# nrf9230_enga_cellrf register map
Vendor: Nordic Semiconductor; Series: nRF92; File version: 1
CPU: CM0 r0p0, little endian, no MPU, no FPU, 2 interrupt priority bits, 33 interrupts
Registers are 32-bit, read-write, reset 0x0 unless marked. A register's access mark holds for its fields unless they carry their own. Offsets are from the block's base; [hi:lo] are bit positions; 'fields as' and 'values as' point back to an identical list.

## RFPLL — RFPLL register map
Base 0x46047000
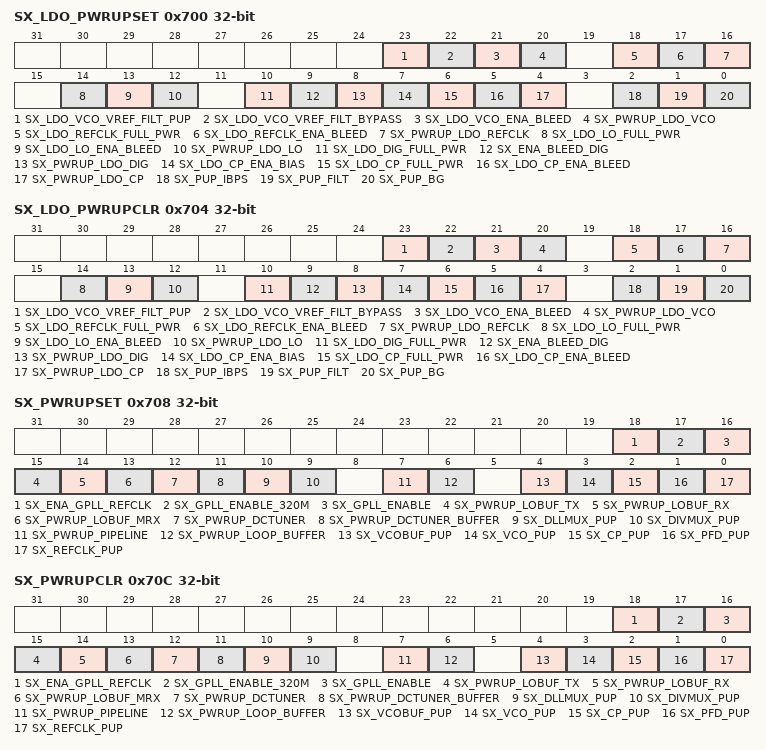
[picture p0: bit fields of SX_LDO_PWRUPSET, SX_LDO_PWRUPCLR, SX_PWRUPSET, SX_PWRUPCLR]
0x700 SX_LDO_PWRUPSET write-1-sets — SX LDO power power up register
  [all] fields
    1=SET (Unspecified); 0=NoEffect (Unspecified)
  [23] SX_LDO_VCO_VREF_FILT_PUP — Enable VREF voltage and its selection logic
  [22] SX_LDO_VCO_VREF_FILT_BYPASS — Bypass large R in VREF RC filter
  [21] SX_LDO_VCO_ENA_BLEED — LDO bleed
  [20] SX_PWRUP_LDO_VCO — LDO power up
  [18] SX_LDO_REFCLK_FULL_PWR — LDO full power
  [17] SX_LDO_REFCLK_ENA_BLEED — LDO bleed
  [16] SX_PWRUP_LDO_REFCLK — LDO power up
  [14] SX_LDO_LO_FULL_PWR — LDO full power
  [13] SX_LDO_LO_ENA_BLEED — LDO bleed
  [12] SX_PWRUP_LDO_LO — LDO power up
  [10] SX_LDO_DIG_FULL_PWR — LDO full power
  [9] SX_ENA_BLEED_DIG — LDO bleed
  [8] SX_PWRUP_LDO_DIG — LDO power up
  [7] SX_LDO_CP_ENA_BIAS — LDO bias power up
  [6] SX_LDO_CP_FULL_PWR — LDO full power
  [5] SX_LDO_CP_ENA_BLEED — LDO bleed
  [4] SX_PWRUP_LDO_CP — LDO power up
  [2] SX_PUP_IBPS — Bias power up
  [1] SX_PUP_FILT — Bias power up
  [0] SX_PUP_BG — Bias power up
0x704 SX_LDO_PWRUPCLR write-1-clears — SX LDO power power down register
  [all] fields
    1=CLR (Unspecified); 0=NoEffect (Unspecified)
  [23] SX_LDO_VCO_VREF_FILT_PUP — Disable VREF voltage and its selection logic
  [22] SX_LDO_VCO_VREF_FILT_BYPASS — Do not bypass large R in VREF RC filter
  [21] SX_LDO_VCO_ENA_BLEED — LDO bleed
  [20] SX_PWRUP_LDO_VCO — LDO power down
  [18] SX_LDO_REFCLK_FULL_PWR — LDO full power
  [17] SX_LDO_REFCLK_ENA_BLEED — LDO bleed
  [16] SX_PWRUP_LDO_REFCLK — LDO power down
  [14] SX_LDO_LO_FULL_PWR — LDO full power
  [13] SX_LDO_LO_ENA_BLEED — LDO bleed
  [12] SX_PWRUP_LDO_LO — LDO power down
  [10] SX_LDO_DIG_FULL_PWR — LDO full power
  [9] SX_ENA_BLEED_DIG — LDO bleed
  [8] SX_PWRUP_LDO_DIG — LDO power down
  [7] SX_LDO_CP_ENA_BIAS — LDO bias power down
  [6] SX_LDO_CP_FULL_PWR — LDO full power
  [5] SX_LDO_CP_ENA_BLEED — LDO bleed
  [4] SX_PWRUP_LDO_CP — LDO power down
  [2] SX_PUP_IBPS — Bias power down
  [1] SX_PUP_FILT — Bias power down
  [0] SX_PUP_BG — Bias power down
0x708 SX_PWRUPSET write-1-sets — SX power up register
  [all] fields
    1=SET (Unspecified); 0=NoEffect (Unspecified)
  [18] SX_ENA_GPLL_REFCLK — Power up
  [17] SX_GPLL_ENABLE_320M — Power up
  [16] SX_GPLL_ENABLE — Power up
  [15] SX_PWRUP_LOBUF_TX — Power up
  [14] SX_PWRUP_LOBUF_RX — Power up
  [13] SX_PWRUP_LOBUF_MRX — Power up
  [12] SX_PWRUP_DCTUNER — Power up
  [11] SX_PWRUP_DCTUNER_BUFFER — Power up
  [10] SX_DLLMUX_PUP — Power up
  [9] SX_DIVMUX_PUP — Power up
  [7] SX_PWRUP_PIPELINE — Power up
  [6] SX_PWRUP_LOOP_BUFFER — Power up
  [4] SX_VCOBUF_PUP — Power up
  [3] SX_VCO_PUP — Power up
  [2] SX_CP_PUP — Power up
  [1] SX_PFD_PUP — Power up
  [0] SX_REFCLK_PUP — Power up
0x70C SX_PWRUPCLR write-1-clears — SX power down register
  [all] fields
    1=CLR (Unspecified); 0=NoEffect (Unspecified)
  [18] SX_ENA_GPLL_REFCLK — Power down
  [17] SX_GPLL_ENABLE_320M — Power down
  [16] SX_GPLL_ENABLE — Power down
  [15] SX_PWRUP_LOBUF_TX — Power down
  [14] SX_PWRUP_LOBUF_RX — Power down
  [13] SX_PWRUP_LOBUF_MRX — Power down
  [12] SX_PWRUP_DCTUNER — Power down
  [11] SX_PWRUP_DCTUNER_BUFFER — Power down
  [10] SX_DLLMUX_PUP — Power down
  [9] SX_DIVMUX_PUP — Power down
  [7] SX_PWRUP_PIPELINE — Power down
  [6] SX_PWRUP_LOOP_BUFFER — Power down
  [4] SX_VCOBUF_PUP — Power down
  [3] SX_VCO_PUP — Power down
  [2] SX_CP_PUP — Power down
  [1] SX_PFD_PUP — Power down
  [0] SX_REFCLK_PUP — Power down
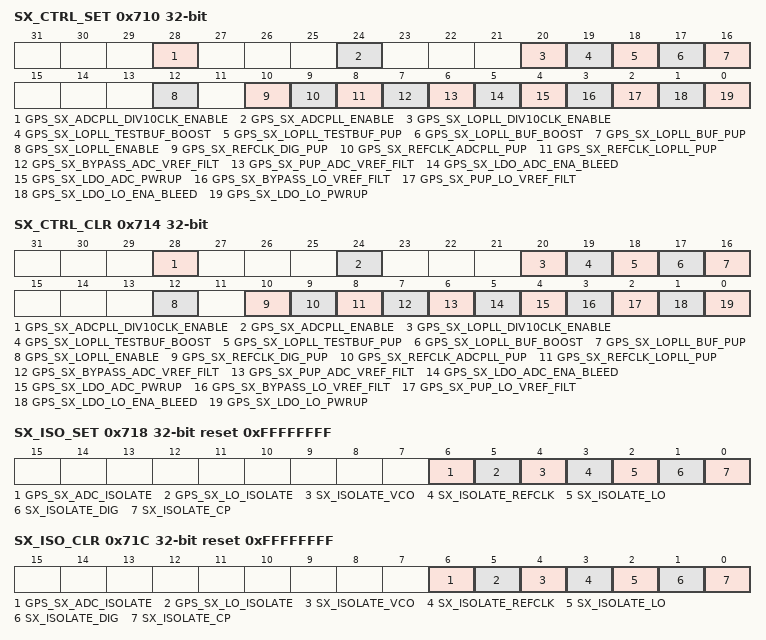
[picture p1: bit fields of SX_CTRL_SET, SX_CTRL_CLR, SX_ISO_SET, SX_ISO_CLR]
0x710 SX_CTRL_SET write-1-sets — SX control set register
  [all] fields
    1=SET (Unspecified); 0=NoEffect (Unspecified)
  [28] GPS_SX_ADCPLL_DIV10CLK_ENABLE — ADCPLL DIV10 output enable
  [24] GPS_SX_ADCPLL_ENABLE — ADCPLL enable
  [20] GPS_SX_LOPLL_DIV10CLK_ENABLE — LOPLL DIV10 output enable
  [19] GPS_SX_LOPLL_TESTBUF_BOOST — LOPLL test output buffer (to LO_OUT) drive boost enable
  [18] GPS_SX_LOPLL_TESTBUF_PUP — LOPLL test output buffer (to LO_OUT) enable
  [17] GPS_SX_LOPLL_BUF_BOOST — LOPLL output buffer drive boost enable
  [16] GPS_SX_LOPLL_BUF_PUP — LOPLL output buffer enable
  [12] GPS_SX_LOPLL_ENABLE — LOPLL enable
  [10] GPS_SX_REFCLK_DIG_PUP — DIG REFCLK signal enable (unused)
  [9] GPS_SX_REFCLK_ADCPLL_PUP — ADCPLL REFCLK signal enable
  [8] GPS_SX_REFCLK_LOPLL_PUP — LOPLL REFCLK signal enable
  [7] GPS_SX_BYPASS_ADC_VREF_FILT — Bypass R in ADCPLL LDO VREF RC filter
  [6] GPS_SX_PUP_ADC_VREF_FILT — ADCPLL LDO VREF voltage enable
  [5] GPS_SX_LDO_ADC_ENA_BLEED — ADCPLL LDO bleed on
  [4] GPS_SX_LDO_ADC_PWRUP — ADCPLL LDO power up
  [3] GPS_SX_BYPASS_LO_VREF_FILT — Bypass R in LOPLL LDO VREF RC filter
  [2] GPS_SX_PUP_LO_VREF_FILT — LOPLL LDO VREF voltage enable
  [1] GPS_SX_LDO_LO_ENA_BLEED — LOPLL LDO bleed on
  [0] GPS_SX_LDO_LO_PWRUP — LOPLL LDO power up
0x714 SX_CTRL_CLR write-1-clears — SX control clr register
  [all] fields
    1=CLR (Unspecified); 0=NoEffect (Unspecified)
  [28] GPS_SX_ADCPLL_DIV10CLK_ENABLE — ADCPLL DIV10 output disable
  [24] GPS_SX_ADCPLL_ENABLE — ADCPLL disable
  [20] GPS_SX_LOPLL_DIV10CLK_ENABLE — LOPLL DIV10 output disable
  [19] GPS_SX_LOPLL_TESTBUF_BOOST — LOPLL test output buffer (to LO_OUT) drive boost disable
  [18] GPS_SX_LOPLL_TESTBUF_PUP — LOPLL test output buffer (to LO_OUT) disable
  [17] GPS_SX_LOPLL_BUF_BOOST — LOPLL output buffer drive boost disable
  [16] GPS_SX_LOPLL_BUF_PUP — LOPLL output buffer disable
  [12] GPS_SX_LOPLL_ENABLE — LOPLL disable
  [10] GPS_SX_REFCLK_DIG_PUP — DIG REFCLK signal disable (unused)
  [9] GPS_SX_REFCLK_ADCPLL_PUP — ADCPLL REFCLK signal disable
  [8] GPS_SX_REFCLK_LOPLL_PUP — LOPLL REFCLK signal disable
  [7] GPS_SX_BYPASS_ADC_VREF_FILT — Don't bypass R in ADCPLL LDO VREF RC filter
  [6] GPS_SX_PUP_ADC_VREF_FILT — ADCPLL LDO VREF voltage disable
  [5] GPS_SX_LDO_ADC_ENA_BLEED — ADCPLL LDO bleed off
  [4] GPS_SX_LDO_ADC_PWRUP — ADCPLL LDO power down
  [3] GPS_SX_BYPASS_LO_VREF_FILT — Don't bypass R in LOPLL LDO VREF RC filter
  [2] GPS_SX_PUP_LO_VREF_FILT — LOPLL LDO VREF voltage disable
  [1] GPS_SX_LDO_LO_ENA_BLEED — LOPLL LDO bleed off
  [0] GPS_SX_LDO_LO_PWRUP — LOPLL LDO power down
0x718 SX_ISO_SET reset 0xFFFFFFFF write-1-sets — SX isolation set register
  [all] fields
    1=SET (Unspecified); 0=NoEffect (Unspecified)
  [6] GPS_SX_ADC_ISOLATE — Tie control signals in the AVDD_GPS_ADC_0V8 domain to AVSS
  [5] GPS_SX_LO_ISOLATE — Tie control signals in the AVDD_GPS_LO_0V8 domain to AVSS
  [4] SX_ISOLATE_VCO — Tie control signals in the AVDD_0V8_VCO domain to AVSS
  [3] SX_ISOLATE_REFCLK — Tie control signals in the AVDD_0V8_REFCLK domain to AVSS
  [2] SX_ISOLATE_LO — Tie control signals in the AVDD_0V8_LO domain to AVSS
  [1] SX_ISOLATE_DIG — Tie control signals in the AVDD_0V8_DIG domain to AVSS
  [0] SX_ISOLATE_CP — Tie control signals in the AVDD_0V8_CP domain to AVSS
0x71C SX_ISO_CLR reset 0xFFFFFFFF write-1-clears — SX isolation clr register
  [all] fields
    1=CLR (Unspecified); 0=NoEffect (Unspecified)
  [6] GPS_SX_ADC_ISOLATE — Release control signals in the AVDD_GPS_ADC_0V8 domain from AVSS
  [5] GPS_SX_LO_ISOLATE — Release control signals in the AVDD_GPS_LO_0V8 domain from AVSS
  [4] SX_ISOLATE_VCO — Release control signals in the AVDD_0V8_VCO domain from AVSS
  [3] SX_ISOLATE_REFCLK — Release control signals in the AVDD_0V8_REFCLK domain from AVSS
  [2] SX_ISOLATE_LO — Release control signals in the AVDD_0V8_LO domain from AVSS
  [1] SX_ISOLATE_DIG — Release control signals in the AVDD_0V8_DIG domain from AVSS
  [0] SX_ISOLATE_CP — Release control signals in the AVDD_0V8_CP domain from AVSS
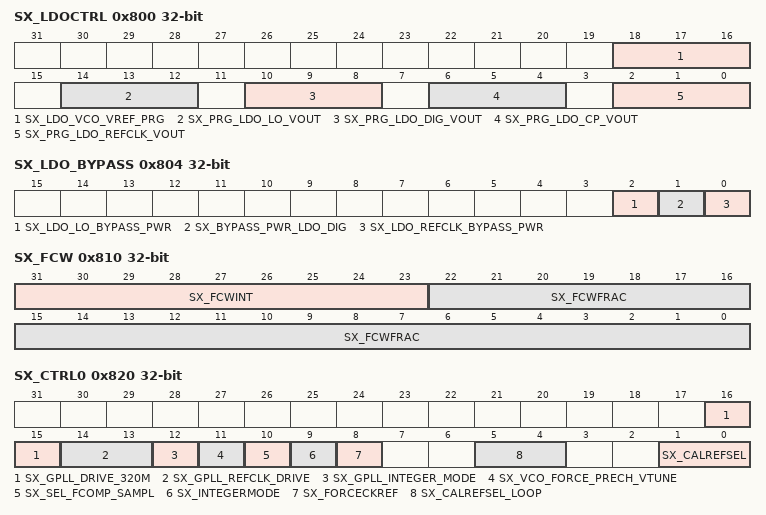
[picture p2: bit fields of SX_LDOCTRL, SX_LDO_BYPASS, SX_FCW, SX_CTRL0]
0x800 SX_LDOCTRL — SX LDO control
  [18:16] SX_LDO_VCO_VREF_PRG — Programmable output voltage of the VCO LDO
    0=800mV (default); 1=825mV (Unspecified); 2=850mV (Unspecified); 3=900mV (Unspecified); 7=750mV (Unspecified); 6=700mV (Unspecified); 5=650mV (Unspecified); 4=600mV (Unspecified)
  [14:12] SX_PRG_LDO_LO_VOUT — Programmable output voltage of the LO LDO
    0=800mV (default); 1=825mV (Unspecified); 2=850mV (Unspecified); 3=875mV (Unspecified); 7=775mV (Unspecified); 6=750mV (Unspecified); 5=725mV (Unspecified); 4=700mV (Unspecified)
  [10:8] SX_PRG_LDO_DIG_VOUT — Programmable output voltage of the DIG LDO
    values as SX_LDO_VCO_VREF_PRG
  [6:4] SX_PRG_LDO_CP_VOUT — Programmable output voltage of the CP LDO
    values as SX_LDO_VCO_VREF_PRG
  [2:0] SX_PRG_LDO_REFCLK_VOUT — Programmable output voltage of the REFCLK LDO
    values as SX_LDO_VCO_VREF_PRG
0x804 SX_LDO_BYPASS
  [all] fields
    1=Bypass (don't use); 0=NoEffect (default)
  [2] SX_LDO_LO_BYPASS_PWR — Bypasses the output PMOS in the LO LDO
  [1] SX_BYPASS_PWR_LDO_DIG — Bypasses the output PMOS in the DIG LDO
  [0] SX_LDO_REFCLK_BYPASS_PWR — Bypasses the output PMOS in the REFCLK LDO
0x808 SX_R_TRIM — SX R trimming control
  [3:0] SX_IBPS_R_TRIM — Trimming control word for 10uA IBPS reference bias current
    0=typ (default, twos complement coding); 8=min (Unspecified); 7=max (Unspecified)
0x80C SX_SWRESET
  [0] SX_ARST — General asynchronous reset
    1=Reset (Unspecified); 0=NoReset (Unspecified)
0x810 SX_FCW
  [31:23] SX_FCWINT — Integer part of the Frequency control word
    0=minFreq (Unspecified)
  [22:0] SX_FCWFRAC — Fractional part of the Frequency control word
    0=minFreq (Unspecified)
0x818 STROBE_SX_AFCREQ wo — SX AFC request
  [0] SX_AFC_REQ — Automatic Frequency Change request, without full PLL calibration
    0=NoEffect (Active on rising edge); 1=Request (Unspecified)
0x81C STROBE_SX_CALREQ wo — SX Calibration request
  [0] SX_CAL_REQ — Calibration request
    0=NoEffect (Active on rising edge); 1=Request (Unspecified)
0x820 SX_CTRL0 — SX control register0
  [16:15] SX_GPLL_DRIVE_320M — GPLL 320MHz clock output drive strength selection
    0=min (Unspecified); 3=max (Unspecified)
  [14:13] SX_GPLL_REFCLK_DRIVE — GPLL Reference clock drive strength selection
    0=min (Unspecified); 3=max (Unspecified)
  [12] SX_GPLL_INTEGER_MODE — GPLL Sigma delta mode selector
    0=fractional (Unspecified); 1=integer (Unspecified)
  [11] SX_VCO_FORCE_PRECH_VTUNE — Cut PLL loop and force precharger voltage on VCO varactor (set by SX_CALREFSEL)
    0=Internal_Vtune_forcing_disabled (Unspecified); 1=Internal_Vtune_forcing_with_CALREFSEL (Unspecified)
  [10] SX_SEL_FCOMP_SAMPL — Resampling of FCOMP signal
    0=Resampling_disabled (Unspecified); 1=Resampling_active_with_ckpipeline (Unspecified)
  [9] SX_INTEGERMODE — RFPLL Sigma delta mode selector
    0=fractional (Unspecified); 1=integer (Unspecified)
  [8] SX_FORCECKREF — Force ckref for FsDivNSdm
    0=Gating_ckref_after_calibration (Unspecified); 1=Continous_ckref_to_FsDivNSdm (Unspecified)
  [5:4] SX_CALREFSEL_LOOP — Selection of CP loop side voltage during VCO calibration
    0=400mV_at_25C (Unspecified); 1=300mV (Unspecified); 2=400mV (Unspecified); 3=500mV (Unspecified)
  [1:0] SX_CALREFSEL — Selection of VCO varactor biasing during VCO calibration
    values as SX_CALREFSEL_LOOP
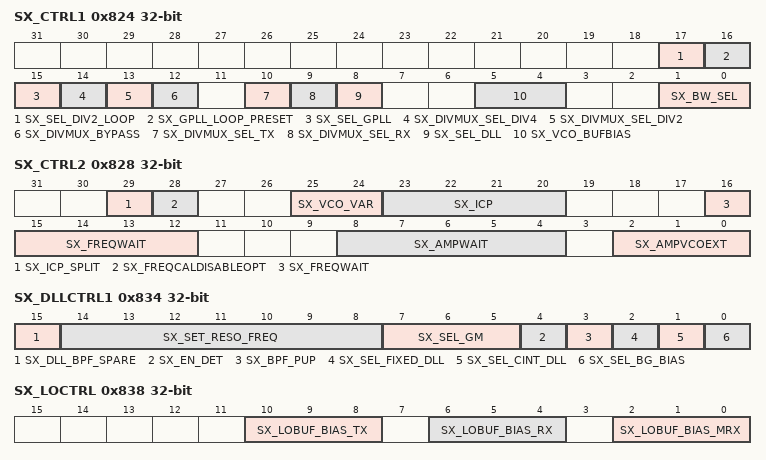
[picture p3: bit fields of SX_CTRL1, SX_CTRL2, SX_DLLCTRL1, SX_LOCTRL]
0x824 SX_CTRL1 — SX control register1
  [17] SX_SEL_DIV2_LOOP — Selection bit for loop division ratio
    0=DIV1 (Unspecified); 1=DIV2 (Unspecified)
  [16] SX_GPLL_LOOP_PRESET — Selection bit for GPS loop voltage preset
    0=GPLL_loop_voltage_not_set (Unspecified); 1=GPLL_loop_voltage_set_to_VDD_div2 (Unspecified)
  [15] SX_SEL_GPLL — Selection bit for GPS LO branch
    0=LO_from_GPLL_disabled (Unspecified); 1=LO_from_GPLL_enabled (Unspecified)
  [14] SX_DIVMUX_SEL_DIV4 — Selection bit for the DIV4 branch
    1=Enable (Unspecified); 0=NoEffect (Unspecified)
  [13] SX_DIVMUX_SEL_DIV2 — Selection bit for the DIV2 branch
    1=Enable (Unspecified); 0=NoEffect (Unspecified)
  [12] SX_DIVMUX_BYPASS — Selection bit for the bypass branch
    1=Enable (Unspecified); 0=NoEffect (Unspecified)
  [10] SX_DIVMUX_SEL_TX — Selection bit for the TX output branch
    1=Enable (Unspecified); 0=NoEffect (Unspecified)
  [9] SX_DIVMUX_SEL_RX — Selection bit for the RX output branch
    1=Enable (Unspecified); 0=NoEffect (Unspecified)
  [8] SX_SEL_DLL — Selection bit for the DLL block
    1=DLLselected (Unspecified); 0=NoEffect (Unspecified)
  [5:4] SX_VCO_BUFBIAS — VCO output buffer voltage swing selection
    0=min (Unspecified); 3=max (Unspecified)
  [1:0] SX_BW_SEL — Adjust the PLL bandwidth
    0=minBW (Unspecified); 3=maxBW (Unspecified)
0x828 SX_CTRL2 — SX control register2
  [29] SX_ICP_SPLIT — Charge pump reference current halving (compared to values indicated by SX_ICP)
    0=ICP_split_disabled (Unspecified); 1=ICP_split_enabled (Unspecified)
  [28] SX_FREQCALDISABLEOPT — Disable utilization of optimal frequency calibration word
    1=Disable (Unspecified); 0=NoEffect (Unspecified)
  [25:24] SX_VCO_VAR — VCO varactor setting
    0=min (Unspecified); 3=max (Unspecified)
  [23:20] SX_ICP — Select the charge pump current, 5uA step
    0=30uA (Unspecified); 15=105uA (Unspecified)
  [16:12] SX_FREQWAIT — Number of additional Tref periods to ensure the settling of the VCO between two successive frequency measurements during SX calibration. min delay 0.5 x Tref
    0=min (Unspecified); 31=max (Unspecified)
  [8:4] SX_AMPWAIT — Number of additional Tref periods to ensure the settling of the VCO between two successive amplitude measurements during SX calibration. min delay 0.5 x Tref
    0=min (Unspecified); 31=max (Unspecified)
  [2:0] SX_AMPVCOEXT — Select the target VCO amplitude level for SX calibration
    0=min (Unspecified); 4=typ (Unspecified); 7=max (Unspecified)
0x834 SX_DLLCTRL1 — SX DLL control register 1
  [15] SX_DLL_BPF_SPARE — Spare bit
  [14:8] SX_SET_RESO_FREQ — Adjust BPF center frequency
    0=min (Unspecified); 127=max (Unspecified)
  [7:5] SX_SEL_GM — Adjust drive power at BPF input
    0=min (Unspecified); 7=max (Unspecified)
  [4] SX_EN_DET — Enable signal for BPF peak detector
    1=PoweredUp (Unspecified); 0=PoweredDown (Unspecified)
  [3] SX_BPF_PUP — Enable signal for bandpass filter
    1=PoweredUp (Unspecified); 0=PoweredDown (Unspecified)
  [2] SX_SEL_FIXED_DLL — Additional parallel stages in delay line of DLL
    1=Selected (Unspecified); 0=NoEffect (Unspecified)
  [1] SX_SEL_CINT_DLL — DLL CP internal filtering capacitor
    1=Selected (Unspecified); 0=NoEffect (Unspecified)
  [0] SX_SEL_BG_BIAS — Backgate bias selection for the delay line inverters of the DLL
    1=Inverted (PMOStoAVDD_NMOStoAVSS); 0=NoEffect (PMOStoAVSS_NMOStoAVDD)
0x838 SX_LOCTRL — SX LO control register
  [all] fields
    0=min (Unspecified); 7=max (Unspecified)
  [10:8] SX_LOBUF_BIAS_TX — LO Line buffer biasing for the TX line
  [6:4] SX_LOBUF_BIAS_RX — LO Line buffer biasing for the RX line
  [2:0] SX_LOBUF_BIAS_MRX — LO Line buffer biasing for the MRX line
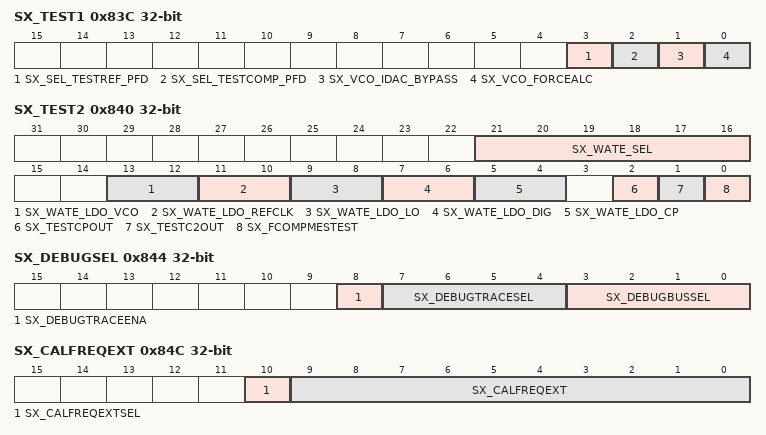
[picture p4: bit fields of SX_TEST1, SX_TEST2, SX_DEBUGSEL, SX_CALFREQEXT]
0x83C SX_TEST1
  [3] SX_SEL_TESTREF_PFD — Testmode selection for PFD (fref input)
    1=Enabled (Unspecified); 0=Noeffect (Unspecified)
  [2] SX_SEL_TESTCOMP_PFD — Testmode selection for PFD (comp input)
    1=Enabled (Unspecified); 0=Noeffect (Unspecified)
  [1] SX_VCO_IDAC_BYPASS — Bypass of VCO bias current resistor matrix (i.e., provides maximum bias current). Use for debug purposes only.
    1=Bypass (Unspecified); 0=Noeffect (Unspecified)
  [0] SX_VCO_FORCEALC — Power-up for VCO voltage swing indicator circuit. Use for debug purposes only.
    1=Enabled (Unspecified); 0=Noeffect (Unspecified)
0x840 SX_TEST2
  [21:16] SX_WATE_SEL — Selection bits for testoutputs
    1=TST_IBPS10UA_toWATB0 (TST_IBPS10UA to WATB OUT0); 2=AVSS_toWATB1 (AVSS to WATB OUT1); 4=CPOUT_EXT_toWATB0 (CPOUT_EXT to WATB OUT0); 8=C2OUT_EXT_toWATB1 (C2OUT_EXT to WATB OUT1); 16=VAMPL_DET_toWATB0 (VAMPL_DET to WATB OUT0); 32=VREF_DET_toWATB1 (VREF_DET to WATB OUT1)
  [13:12] SX_WATE_LDO_VCO — Selection bits for VCO LDO testoutputs
    0=disconnected (No connection); 1=LDO output to WATB OUT0; 2=AVSS_VCO (AVSS_VCO to WATB OUT1)
  [11:10] SX_WATE_LDO_REFCLK — Selection bits for REFCLK LDO testoutputs
    0=disconnected (No connection); 1=LDO output to WATB OUT0; 2=LDO input to WATB OUT1
  [9:8] SX_WATE_LDO_LO — Selection bits for LO LDO testoutputs
    values as SX_WATE_LDO_REFCLK
  [7:6] SX_WATE_LDO_DIG — Selection bits for DIG LDO testoutputs
    values as SX_WATE_LDO_REFCLK
  [5:4] SX_WATE_LDO_CP — Selection bits for CP LDO testoutputs
    values as SX_WATE_LDO_REFCLK
  [2] SX_TESTCPOUT — Loop filter test output 2
    1=Enabled (CPOUT to WATB OUT0); 0=Noeffect ((SX_WATE_SEL also needed))
  [1] SX_TESTC2OUT — Loop filter test output 1
    1=Enabled (C2OUT to WATB OUT1); 0=Noeffect ((SX_WATE_SEL also needed))
  [0] SX_FCOMPMESTEST — fcompMeas output
    1=Enabled (Unspecified); 0=Noeffect (Unspecified)
0x844 SX_DEBUGSEL
  [8] SX_DEBUGTRACEENA — Enable debug bus trace registers
    1=Enabled (Unspecified); 0=Noeffect (Unspecified)
  [7:4] SX_DEBUGTRACESEL — Selection for calibration step to be monitored
    0=window0 (Unspecified)
  [3:0] SX_DEBUGBUSSEL — Selection for debugbus output
0x848 SX_SPAREIN
  [15:0] SX_SPAREIN
0x84C SX_CALFREQEXT
  [10] SX_CALFREQEXTSEL — Use the external VCO frequency calibration control word instead of the automatic calibration result
    1=Enabled (Unspecified); 0=Noeffect (Unspecified)
  [9:0] SX_CALFREQEXT — Externally forced VCO frequency calibration control word
    0=min (Unspecified); 0x3FF=max (Unspecified)
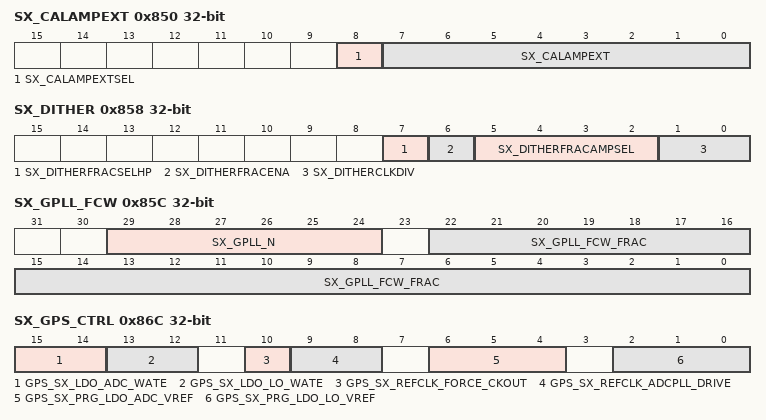
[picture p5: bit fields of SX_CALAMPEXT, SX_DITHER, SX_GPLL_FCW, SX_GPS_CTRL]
0x850 SX_CALAMPEXT
  [8] SX_CALAMPEXTSEL — Use the external VCO amplitude calibration control word instead of the automatic calibration result
    1=Enabled (Unspecified); 0=Noeffect (Unspecified)
  [7:0] SX_CALAMPEXT — Externally forced VCO amplitude calibration control word (thermometer-coded)
    0=min (Unspecified)
0x854 SX_CALEXTSTROBE
  [0] SX_EXTCTRLUPDSTROBE — Strobe pulse indicating changed external controls. Active on rising edge.
    1=Request (Unspecified); 0=Noeffect (Unspecified)
0x858 SX_DITHER
  [7] SX_DITHERFRACSELHP — High Pass -shaped dither for sdm internal dither
    1=Enabled (Unspecified); 0=Noeffect (Unspecified)
  [6] SX_DITHERFRACENA — sdm internal dithering
    1=Enabled (Unspecified); 0=Noeffect (Unspecified)
  [5:2] SX_DITHERFRACAMPSEL — Select the dithered bit in MASH internal signals
    1=Enabled (Unspecified); 0=Noeffect (Unspecified)
  [1:0] SX_DITHERCLKDIV — Select sdm dither clock division
    0=minDivisionRatio (Unspecified)
0x85C SX_GPLL_FCW
  [29:24] SX_GPLL_N — Integer part of the Frequency control word
    0=minFreq (Unspecified)
  [22:0] SX_GPLL_FCW_FRAC — Fractional part of the Frequency control word
    0=minFreq (Unspecified)
0x860 SX_GPLL_SWRESET
  [0] SX_GPLL_ARSTSD — General asynchronous reset
    1=Reset (Unspecified); 0=NoReset (Unspecified)
0x864 SX_GPLL_SPARE
  [3:0] SX_GPLL_SPARE_IN — Spare
0x868 STROBE_SX_GPLL_FCWUPDREQ wo — SX GPLL FCW request
  [0] SX_GPLL_FCW_UPDREQ — Allow the taking into account the new fcw words
    0=NoEffect (Active on rising edge); 1=Request (Unspecified)
0x86C SX_GPS_CTRL
  [15:14] GPS_SX_LDO_ADC_WATE — Selection bits for ADCPLL LDO test outputs
    0=disconnected (No connection); 1=LDO output to WATB OUT0; 2=AVSS (AVSS to WATB OUT1)
  [13:12] GPS_SX_LDO_LO_WATE — Selection bits for LOPLL LDO test outputs
    values as GPS_SX_LDO_ADC_WATE
  [10] GPS_SX_REFCLK_FORCE_CKOUT — Unused
  [9:8] GPS_SX_REFCLK_ADCPLL_DRIVE — Unused
  [6:4] GPS_SX_PRG_LDO_ADC_VREF — Programmable output voltage of the ADCPLL LDO
    values as SX_LDOCTRL.SX_LDO_VCO_VREF_PRG
  [2:0] GPS_SX_PRG_LDO_LO_VREF — Programmable output voltage of the LOPLL LDO
    values as SX_LDOCTRL.SX_LDO_VCO_VREF_PRG
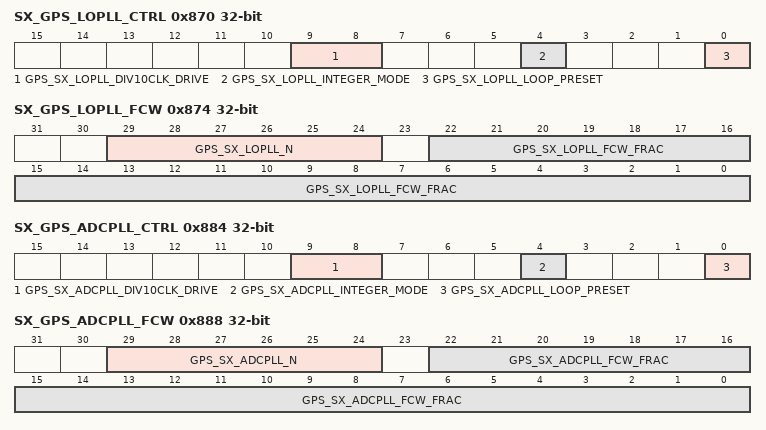
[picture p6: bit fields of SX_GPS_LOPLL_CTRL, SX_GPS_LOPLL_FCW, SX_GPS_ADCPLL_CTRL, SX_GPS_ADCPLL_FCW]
0x870 SX_GPS_LOPLL_CTRL
  [9:8] GPS_SX_LOPLL_DIV10CLK_DRIVE — LOPLL DIV10 clock output drive strength selection
    0=min (Unspecified); 3=max (Unspecified)
  [4] GPS_SX_LOPLL_INTEGER_MODE — LOPLL sigma-delta mode selector
    0=fractional (Unspecified); 1=integer (Unspecified)
  [0] GPS_SX_LOPLL_LOOP_PRESET — LOPLL loop voltage preset setting
    0=release_loop_voltage (Unspecified); 1=set_loop_voltage_to_VDD_div2 (Unspecified)
0x874 SX_GPS_LOPLL_FCW
  [29:24] GPS_SX_LOPLL_N — Integer part of the frequency control word
  [22:0] GPS_SX_LOPLL_FCW_FRAC — Fractional part of the frequency control word
0x878 SX_GPS_LOPLL_SWRESET
  [0] GPS_SX_LOPLL_ARSTSD — LOPLL general asynchronous reset
    1=Reset (Unspecified); 0=NoReset (Unspecified)
0x87C SX_GPS_LOPLL_SPARE
  [3:0] GPS_SX_LOPLL_SPARE_IN — Spare
0x880 STROBE_SX_GPS_LOPLL_FCWUPDREQ wo — SX_GPS_LOPLL_FCWUPDREQ
  [0] GPS_SX_LOPLL_FCW_UPDREQ — Activate the new frequency control word
    0=NoEffect (Active on rising edge); 1=Request (Unspecified)
0x884 SX_GPS_ADCPLL_CTRL
  [9:8] GPS_SX_ADCPLL_DIV10CLK_DRIVE — ADCPLL DIV10 clock output drive strength selection
    0=min (Unspecified); 3=max (Unspecified)
  [4] GPS_SX_ADCPLL_INTEGER_MODE — ADCPLL sigma-delta mode selector
    0=fractional (Unspecified); 1=integer (Unspecified)
  [0] GPS_SX_ADCPLL_LOOP_PRESET — ADCPLL loop voltage preset setting
    values as SX_GPS_LOPLL_CTRL.GPS_SX_LOPLL_LOOP_PRESET
0x888 SX_GPS_ADCPLL_FCW
  [29:24] GPS_SX_ADCPLL_N — Integer part of the frequency control word
  [22:0] GPS_SX_ADCPLL_FCW_FRAC — Fractional part of the frequency control word
0x88C SX_GPS_ADCPLL_SWRESET
  [0] GPS_SX_ADCPLL_ARSTSD — ADCPLL general asynchronous reset
    1=Reset (Unspecified); 0=NoReset (Unspecified)
0x890 SX_GPS_ADCPLL_SPARE
  [3:0] GPS_SX_ADCPLL_SPARE_IN — Spare
0x894 STROBE_SX_GPS_ADCPLL_FCWUPDREQ wo — SX_GPS_ADCPLL_FCWUPDREQ
  [0] GPS_SX_ADCPLL_FCW_UPDREQ — Activate the new frequency control word
    0=NoEffect (Active on rising edge); 1=Request (Unspecified)
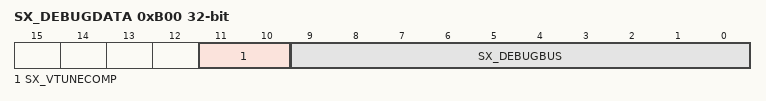
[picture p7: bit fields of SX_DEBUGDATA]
0xB00 SX_DEBUGDATA ro
  [11:10] SX_VTUNECOMP — Spare
  [9:0] SX_DEBUGBUS — Data bus containing selected debug information
